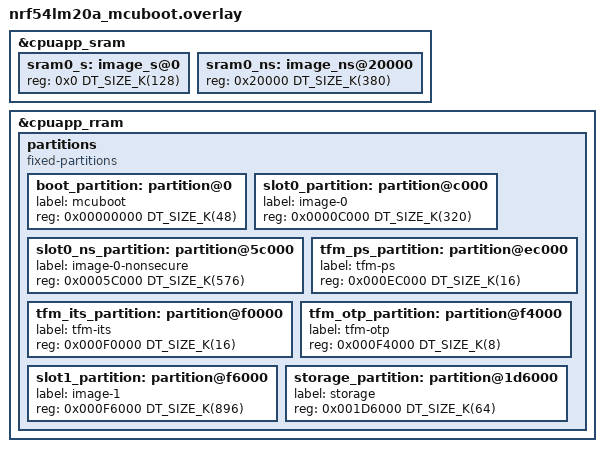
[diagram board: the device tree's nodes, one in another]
/*
 * Copyright (c) 2026 Nordic Semiconductor ASA
 *
 * SPDX-License-Identifier: LicenseRef-Nordic-5-Clause
 */

/*
 * TF-M partition layout with MCUboot for nRF54LM20A
 *
 * nRF54LM20A has 2036 kB of RRAM and 512 kB of SRAM (508 kB usable).
 * TrustZone flash region alignment: 4 kB (MPC-based)
 * TrustZone RAM region alignment:   4 kB
 * RRAM erase-block-size:            4 kB
 *
 * The large RRAM allows generous primary and secondary DFU slots
 * with room for TF-M storage partitions.
 *
 * Suitable for: products requiring firmware updates on nRF54LM20A
 */

&cpuapp_sram {
	sram0_s: image_s@0 {
		#address-cells = <1>;
		#size-cells = <1>;
		reg = <0x0 DT_SIZE_K(128)>;
		ranges = <0x0 0x0 DT_SIZE_K(128)>;
	};

	sram0_ns: image_ns@20000 {
		#address-cells = <1>;
		#size-cells = <1>;
		reg = <0x20000 DT_SIZE_K(380)>;
		ranges = <0x0 0x20000 DT_SIZE_K(380)>;
	};
};

&cpuapp_rram {
	partitions {
		compatible = "fixed-partitions";
		#address-cells = <1>;
		#size-cells = <1>;

		/*
		 * Flash layout (all addresses 4 kB aligned):
		 *
		 * 0x00000000  MCUboot bootloader        (48 kB)
		 * 0x0000C000  Primary slot:
		 *   0x0000C000  TF-M secure image       (320 kB)
		 *   0x0005C000  Non-secure application   (576 kB)
		 * 0x000EC000  TF-M PS                    (16 kB)
		 * 0x000F0000  TF-M ITS                   (16 kB)
		 * 0x000F4000  TF-M OTP / NV counters      (8 kB)
		 * 0x000F6000  Secondary slot            (896 kB)
		 * 0x001D6000  Non-secure storage         (64 kB)
		 *
		 * Primary = 320 + 576 = 896 kB = Secondary
		 * Total: 48 + 896 + 16 + 16 + 8 + 896 + 64 = 1944 kB
		 */

		boot_partition: partition@0 {
			label = "mcuboot";
			reg = <0x00000000 DT_SIZE_K(48)>;
		};

		slot0_partition: partition@c000 {
			label = "image-0";
			reg = <0x0000C000 DT_SIZE_K(320)>;
		};

		slot0_ns_partition: partition@5c000 {
			label = "image-0-nonsecure";
			reg = <0x0005C000 DT_SIZE_K(576)>;
		};

		tfm_ps_partition: partition@ec000 {
			label = "tfm-ps";
			reg = <0x000EC000 DT_SIZE_K(16)>;
		};

		tfm_its_partition: partition@f0000 {
			label = "tfm-its";
			reg = <0x000F0000 DT_SIZE_K(16)>;
		};

		tfm_otp_partition: partition@f4000 {
			label = "tfm-otp";
			reg = <0x000F4000 DT_SIZE_K(8)>;
		};

		slot1_partition: partition@f6000 {
			label = "image-1";
			reg = <0x000F6000 DT_SIZE_K(896)>;
		};

		storage_partition: partition@1d6000 {
			label = "storage";
			reg = <0x001D6000 DT_SIZE_K(64)>;
		};
	};
};
